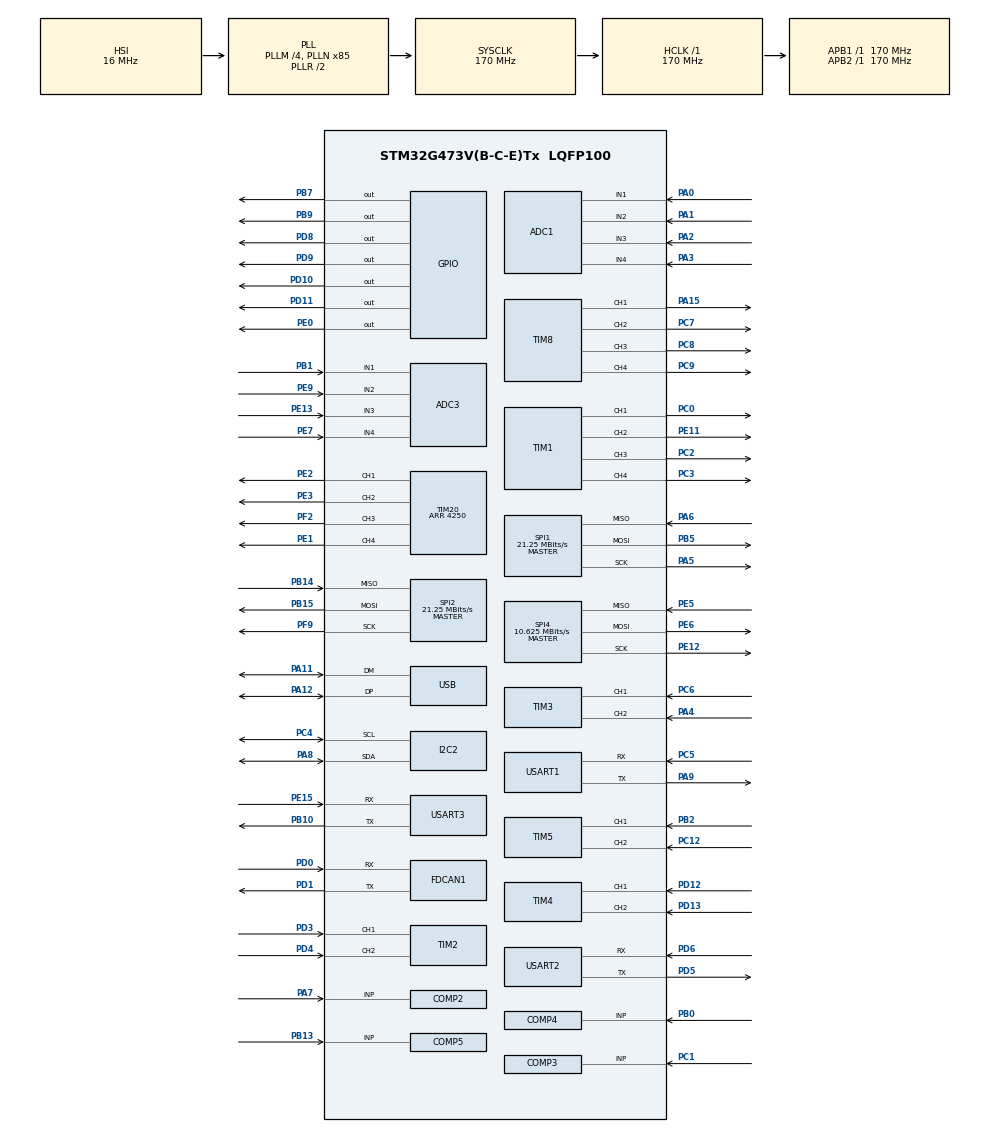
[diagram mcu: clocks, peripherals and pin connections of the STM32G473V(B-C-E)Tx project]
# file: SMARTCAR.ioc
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ADC1.Channel-0\#ChannelRegularConversion=ADC_CHANNEL_1
ADC1.NbrOfConversionFlag=1
ADC1.OffsetNumber-0\#ChannelRegularConversion=ADC_OFFSET_NONE
ADC1.Rank-0\#ChannelRegularConversion=1
ADC1.SamplingTime-0\#ChannelRegularConversion=ADC_SAMPLETIME_2CYCLES_5
ADC1.master=1
ADC3.Channel-0\#ChannelRegularConversion=ADC_CHANNEL_1
ADC3.NbrOfConversionFlag=1
ADC3.OffsetNumber-0\#ChannelRegularConversion=ADC_OFFSET_NONE
ADC3.Rank-0\#ChannelRegularConversion=1
ADC3.SamplingTime-0\#ChannelRegularConversion=ADC_SAMPLETIME_2CYCLES_5
ADC3.master=1
DAC1.DAC_Channel-DAC_OUT2_Int=DAC_CHANNEL_2
DAC3.DAC_Channel-DAC_OUT2_Int=DAC_CHANNEL_2
FDCAN1.CalculateBaudRateNominal=3541666
FDCAN1.CalculateTimeBitNominal=282
FDCAN1.CalculateTimeQuantumNominal=94.11764705882354
FREERTOS.Tasks01=defaultTask,24,128,StartDefaultTask,Default,NULL,Dynamic,NULL,NULL
I2C2.Timing=0x40B285C2
Mcu.Family=STM32G4
Mcu.Name=STM32G473V(B-C-E)Tx
Mcu.Package=LQFP100
NVIC.ADC1_2_IRQn=true\:5\:0\:false\:false\:true\:true\:true\:true\:true
NVIC.PriorityGroup=NVIC_PRIORITYGROUP_4
NVIC.TIM1_UP_TIM16_IRQn=true\:5\:0\:false\:false\:true\:true\:false\:true\:true
NVIC.TIM6_DAC_IRQn=true\:15\:0\:false\:false\:true\:false\:false\:true\:true
NVIC.TIM7_DAC_IRQn=true\:5\:0\:false\:false\:true\:true\:true\:true\:true
NVIC.TimeBase=TIM6_DAC_IRQn
NVIC.TimeBaseIP=TIM6
NVIC.USB_LP_IRQn=true\:5\:0\:false\:false\:true\:true\:false\:true\:true
PA0.Mode=IN1-Single-Ended
PA0.Signal=ADC1_IN1
PA1.Mode=IN2-Single-Ended
PA1.Signal=ADC1_IN2
PA11.Mode=Device
PA11.Signal=USB_DM
PA12.Mode=Device
PA12.Signal=USB_DP
PA13.Mode=Serial_Wire
PA13.Signal=SYS_JTMS-SWDIO
PA14.Mode=Serial_Wire
PA14.Signal=SYS_JTCK-SWCLK
PA15.Signal=S_TIM8_CH1
PA2.Mode=IN3-Single-Ended
PA2.Signal=ADC1_IN3
PA3.Mode=IN4-Single-Ended
PA3.Signal=ADC1_IN4
PA4.Signal=S_TIM3_CH2
PA5.Mode=Full_Duplex_Master
PA5.Signal=SPI1_SCK
PA6.Mode=Full_Duplex_Master
PA6.Signal=SPI1_MISO
PA7.Mode=INP
PA7.Signal=COMP2_INP
PA8.Mode=I2C
PA8.Signal=I2C2_SDA
PA9.Mode=Asynchronous
PA9.Signal=USART1_TX
PB0.Mode=INP
PB0.Signal=COMP4_INP
PB1.Mode=IN1-Single-Ended
PB1.Signal=ADC3_IN1
PB10.Mode=Asynchronous
PB10.Signal=USART3_TX
PB13.Mode=INP
PB13.Signal=COMP5_INP
PB14.Mode=Full_Duplex_Master
PB14.Signal=SPI2_MISO
PB15.Mode=Full_Duplex_Master
PB15.Signal=SPI2_MOSI
PB2.Signal=S_TIM5_CH1
PB5.Mode=Full_Duplex_Master
PB5.Signal=SPI1_MOSI
PB7.Signal=GPIO_Output
PB9.Signal=GPIO_Output
PC0.Signal=S_TIM1_CH1
PC1.Mode=INP
PC1.Signal=COMP3_INP
PC12.Signal=S_TIM5_CH2
PC14-OSC32_IN.Mode=LSE-External-Oscillator
PC14-OSC32_IN.Signal=RCC_OSC32_IN
PC15-OSC32_OUT.Mode=LSE-External-Oscillator
PC15-OSC32_OUT.Signal=RCC_OSC32_OUT
PC2.Signal=S_TIM1_CH3
PC3.Signal=S_TIM1_CH4
PC4.Mode=I2C
PC4.Signal=I2C2_SCL
PC5.Mode=Asynchronous
PC5.Signal=USART1_RX
PC6.Signal=S_TIM3_CH1
PC7.Signal=S_TIM8_CH2
PC8.Signal=S_TIM8_CH3
PC9.Signal=S_TIM8_CH4
PD0.Mode=FDCAN_Activate
PD0.Signal=FDCAN1_RX
PD1.Mode=FDCAN_Activate
PD1.Signal=FDCAN1_TX
PD10.Signal=GPIO_Output
PD11.Signal=GPIO_Output
PD12.Signal=S_TIM4_CH1
PD13.Signal=S_TIM4_CH2
PD3.Signal=S_TIM2_CH1
PD4.Signal=S_TIM2_CH2
PD5.Mode=Asynchronous
PD5.Signal=USART2_TX
PD6.Mode=Asynchronous
PD6.Signal=USART2_RX
PD8.Signal=GPIO_Output
PD9.Signal=GPIO_Output
PE0.Signal=GPIO_Output
PE1.Signal=S_TIM20_CH4
PE11.Signal=S_TIM1_CH2
PE12.Mode=Full_Duplex_Master
PE12.Signal=SPI4_SCK
PE13.Mode=IN3-Single-Ended
PE13.Signal=ADC3_IN3
PE15.Mode=Asynchronous
PE15.Signal=USART3_RX
PE2.Signal=S_TIM20_CH1
PE3.Signal=S_TIM20_CH2
PE5.Mode=Full_Duplex_Master
PE5.Signal=SPI4_MISO
PE6.Mode=Full_Duplex_Master
PE6.Signal=SPI4_MOSI
PE7.Mode=IN4-Single-Ended
PE7.Signal=ADC3_IN4
PE9.Mode=IN2-Single-Ended
PE9.Signal=ADC3_IN2
PF0-OSC_IN.Mode=HSE-External-Oscillator
PF0-OSC_IN.Signal=RCC_OSC_IN
PF1-OSC_OUT.Mode=HSE-External-Oscillator
PF1-OSC_OUT.Signal=RCC_OSC_OUT
PF2.Signal=S_TIM20_CH3
PF9.Mode=Full_Duplex_Master
PF9.Signal=SPI2_SCK
ProjectManager.HeapSize=0x200
ProjectManager.StackSize=0x400
ProjectManager.TargetToolchain=CMake
RCC.ADC12Freq_Value=170000000
RCC.ADC345Freq_Value=170000000
RCC.AHBFreq_Value=170000000
RCC.APB1Freq_Value=170000000
RCC.APB1TimFreq_Value=170000000
RCC.APB2Freq_Value=170000000
RCC.APB2TimFreq_Value=170000000
RCC.CK48CLockSelection=RCC_USBCLKSOURCE_HSI48
RCC.CortexFreq_Value=170000000
RCC.EXTERNAL_CLOCK_VALUE=12288000
RCC.HCLKFreq_Value=170000000
RCC.HSE_VALUE=8000000
RCC.HSI48_VALUE=48000000
RCC.HSI_VALUE=16000000
RCC.PLLM=RCC_PLLM_DIV4
RCC.PLLN=85
RCC.SYSCLKFreq_VALUE=170000000
RCC.SYSCLKSource=RCC_SYSCLKSOURCE_PLLCLK
RCC.USBFreq_Value=48000000
RCC.VCOOutputFreq_Value=340000000
SH.S_TIM1_CH1.0=TIM1_CH1,PWM Generation1 CH1
SH.S_TIM1_CH2.0=TIM1_CH2,PWM Generation2 CH2
SH.S_TIM1_CH3.0=TIM1_CH3,PWM Generation3 CH3
SH.S_TIM1_CH4.0=TIM1_CH4,PWM Generation4 CH4
SH.S_TIM20_CH1.0=TIM20_CH1,PWM Generation1 CH1
SH.S_TIM20_CH2.0=TIM20_CH2,PWM Generation2 CH2
SH.S_TIM20_CH3.0=TIM20_CH3,PWM Generation3 CH3
SH.S_TIM20_CH4.0=TIM20_CH4,PWM Generation4 CH4
SH.S_TIM2_CH1.0=TIM2_CH1,Encoder_Interface
SH.S_TIM2_CH2.0=TIM2_CH2,Encoder_Interface
SH.S_TIM3_CH1.0=TIM3_CH1,Encoder_Interface
SH.S_TIM3_CH2.0=TIM3_CH2,Encoder_Interface
SH.S_TIM4_CH1.0=TIM4_CH1,Encoder_Interface
SH.S_TIM4_CH2.0=TIM4_CH2,Encoder_Interface
SH.S_TIM5_CH1.0=TIM5_CH1,Encoder_Interface
SH.S_TIM5_CH2.0=TIM5_CH2,Encoder_Interface
SH.S_TIM8_CH1.0=TIM8_CH1,PWM Generation1 CH1
SH.S_TIM8_CH2.0=TIM8_CH2,PWM Generation2 CH2
SH.S_TIM8_CH3.0=TIM8_CH3,PWM Generation3 CH3
SH.S_TIM8_CH4.0=TIM8_CH4,PWM Generation4 CH4
SPI1.BaudRatePrescaler=SPI_BAUDRATEPRESCALER_8
SPI1.CalculateBaudRate=21.25 MBits/s
SPI1.Direction=SPI_DIRECTION_2LINES
SPI1.Mode=SPI_MODE_MASTER
SPI1.VirtualType=VM_MASTER
SPI2.BaudRatePrescaler=SPI_BAUDRATEPRESCALER_8
SPI2.CalculateBaudRate=21.25 MBits/s
SPI2.Direction=SPI_DIRECTION_2LINES
SPI2.Mode=SPI_MODE_MASTER
SPI2.VirtualType=VM_MASTER
SPI4.BaudRatePrescaler=SPI_BAUDRATEPRESCALER_16
SPI4.CalculateBaudRate=10.625 MBits/s
SPI4.Direction=SPI_DIRECTION_2LINES
SPI4.Mode=SPI_MODE_MASTER
SPI4.VirtualType=VM_MASTER
TIM1.Channel-PWM\ Generation1\ CH1=TIM_CHANNEL_1
TIM1.Channel-PWM\ Generation2\ CH2=TIM_CHANNEL_2
TIM1.Channel-PWM\ Generation3\ CH3=TIM_CHANNEL_3
TIM1.Channel-PWM\ Generation4\ CH4=TIM_CHANNEL_4
TIM2.EncoderMode=TIM_ENCODERMODE_TI12
TIM20.Channel-PWM\ Generation1\ CH1=TIM_CHANNEL_1
TIM20.Channel-PWM\ Generation2\ CH2=TIM_CHANNEL_2
TIM20.Channel-PWM\ Generation3\ CH3=TIM_CHANNEL_3
TIM20.Channel-PWM\ Generation4\ CH4=TIM_CHANNEL_4
TIM20.PeriodNoDither=4250
TIM3.EncoderMode=TIM_ENCODERMODE_TI12
TIM4.EncoderMode=TIM_ENCODERMODE_TI12
TIM5.EncoderMode=TIM_ENCODERMODE_TI12
TIM7.PeriodNoDither=999
TIM7.Prescaler=169
TIM8.Channel-PWM\ Generation1\ CH1=TIM_CHANNEL_1
TIM8.Channel-PWM\ Generation2\ CH2=TIM_CHANNEL_2
TIM8.Channel-PWM\ Generation3\ CH3=TIM_CHANNEL_3
TIM8.Channel-PWM\ Generation4\ CH4=TIM_CHANNEL_4
USART1.VirtualMode-Asynchronous=VM_ASYNC
USART2.VirtualMode-Asynchronous=VM_ASYNC
USART3.VirtualMode-Asynchronous=VM_ASYNC
USB_DEVICE.CLASS_NAME_FS=CDC
USB_DEVICE.VirtualMode=Cdc
USB_DEVICE.VirtualModeFS=Cdc_FS
VP_ADC1_TempSens_Input.Mode=IN-TempSens
VP_COMP2_VS_DAC1OUT2.Mode=INM_DAC1OUT2
VP_COMP3_VS_DAC1OUT1.Mode=INM_DAC1OUT1
VP_COMP4_VS_DAC3OUT2.Mode=INM_DAC3OUT2
VP_COMP5_VS_DAC4OUT1.Mode=INM_DAC4OUT1
VP_CORDIC_VS_CORDIC.Mode=CORDIC_Activate
VP_CRC_VS_CRC.Mode=CRC_Activate
VP_DAC1_VS_DACI1.Mode=DAC_OUT1_Int
VP_DAC1_VS_DACI2.Mode=DAC_OUT2_Int
VP_DAC3_VS_DACI2.Mode=DAC_OUT2_Int
VP_DAC4_VS_DACI1.Mode=DAC_OUT1_Int
VP_FMAC_VS_FMAC.Mode=FMAC_Activate
VP_FREERTOS_VS_CMSIS_V2.Mode=CMSIS_V2
VP_IWDG_VS_IWDG.Mode=IWDG_Activate
VP_SYS_VS_DBSignals.Mode=DisableDeadBatterySignals
VP_SYS_VS_tim6.Mode=TIM6
VP_TIM7_VS_ClockSourceINT.Mode=Enable_Timer
VP_USB_DEVICE_VS_USB_DEVICE_CDC_FS.Mode=CDC_FS
board=custom

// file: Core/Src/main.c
/* USER CODE BEGIN Header */
/**
  ******************************************************************************
  * @file           : main.c
  * @brief          : Main program body
  ******************************************************************************
  * @attention
  *
  * Copyright (c) 2026 STMicroelectronics.
  * All rights reserved.
  *
  * This software is licensed under terms that can be found in the LICENSE file
  * in the root directory of this software component.
  * If no LICENSE file comes with this software, it is provided AS-IS.
  *
  ******************************************************************************
  */
/* USER CODE END Header */
#include "main.h"

#include "cmsis_os.h"
#include "usb_device.h"

/* USER CODE BEGIN Includes */
#include "app_main.h"
/* USER CODE END Includes */

ADC_HandleTypeDef hadc1;
ADC_HandleTypeDef hadc3;

COMP_HandleTypeDef hcomp2;
COMP_HandleTypeDef hcomp3;
COMP_HandleTypeDef hcomp4;
COMP_HandleTypeDef hcomp5;

CORDIC_HandleTypeDef hcordic;

CRC_HandleTypeDef hcrc;

DAC_HandleTypeDef hdac1;
DAC_HandleTypeDef hdac3;
DAC_HandleTypeDef hdac4;

FDCAN_HandleTypeDef hfdcan1;

FMAC_HandleTypeDef hfmac;

I2C_HandleTypeDef hi2c2;

IWDG_HandleTypeDef hiwdg;

SPI_HandleTypeDef hspi1;
SPI_HandleTypeDef hspi2;
SPI_HandleTypeDef hspi4;

TIM_HandleTypeDef htim1;
TIM_HandleTypeDef htim2;
TIM_HandleTypeDef htim3;
TIM_HandleTypeDef htim4;
TIM_HandleTypeDef htim5;
TIM_HandleTypeDef htim7;
TIM_HandleTypeDef htim8;
TIM_HandleTypeDef htim20;

UART_HandleTypeDef huart1;
UART_HandleTypeDef huart2;
UART_HandleTypeDef huart3;

/* Definitions for defaultTask */
osThreadId_t defaultTaskHandle;
const osThreadAttr_t defaultTask_attributes = {
    .name = "defaultTask",
    .priority = (osPriority_t) osPriorityNormal,
    .stack_size = 128 * 4
};

void SystemClock_Config(void);

static void MX_GPIO_Init(void);

static void MX_ADC1_Init(void);

static void MX_ADC3_Init(void);

static void MX_COMP2_Init(void);

static void MX_COMP3_Init(void);

static void MX_COMP4_Init(void);

static void MX_COMP5_Init(void);

static void MX_CORDIC_Init(void);

static void MX_CRC_Init(void);

static void MX_DAC1_Init(void);

static void MX_DAC3_Init(void);

static void MX_DAC4_Init(void);

static void MX_FDCAN1_Init(void);

static void MX_FMAC_Init(void);

static void MX_I2C2_Init(void);

static void MX_IWDG_Init(void);

static void MX_SPI1_Init(void);

static void MX_SPI2_Init(void);

static void MX_TIM1_Init(void);

static void MX_TIM2_Init(void);

static void MX_TIM3_Init(void);

static void MX_TIM4_Init(void);

static void MX_TIM5_Init(void);

static void MX_TIM8_Init(void);

static void MX_TIM20_Init(void);

static void MX_USART1_UART_Init(void);

static void MX_USART2_UART_Init(void);

static void MX_USART3_UART_Init(void);

static void MX_SPI4_Init(void);

static void MX_TIM7_Init(void);

void StartDefaultTask(void *argument);

int main(void) {

    /* MCU Configuration--------------------------------------------------------*/

    /* Reset of all peripherals, Initializes the Flash interface and the Systick. */
    HAL_Init();

    /* Configure the system clock */
    SystemClock_Config();

    /* Initialize all configured peripherals */
    MX_GPIO_Init();
    MX_ADC1_Init();
    MX_ADC3_Init();
    MX_COMP2_Init();
    MX_COMP3_Init();
    MX_COMP4_Init();
    MX_COMP5_Init();
    MX_CORDIC_Init();
    MX_CRC_Init();
    MX_DAC1_Init();
    MX_DAC3_Init();
    MX_DAC4_Init();
    MX_FDCAN1_Init();
    MX_FMAC_Init();
    MX_I2C2_Init();
    MX_IWDG_Init();
    MX_SPI1_Init();
    MX_SPI2_Init();
    MX_TIM1_Init();
    MX_TIM2_Init();
    MX_TIM3_Init();
    MX_TIM4_Init();
    MX_TIM5_Init();
    MX_TIM8_Init();
    MX_TIM20_Init();
    MX_USART1_UART_Init();
    MX_USART2_UART_Init();
    MX_USART3_UART_Init();
    MX_SPI4_Init();
    MX_TIM7_Init();
    /* USER CODE BEGIN 2 */

    HAL_Delay(100);
    App_Init();
    App_Main();
    /* USER CODE END 2 */

    /* Init scheduler */
    osKernelInitialize();

    /* Create the thread(s) */
    /* creation of defaultTask */
    defaultTaskHandle = osThreadNew(StartDefaultTask, NULL, &defaultTask_attributes);

    /* Start scheduler */
    osKernelStart();

    /* We should never get here as control is now taken by the scheduler */

    /* Infinite loop */
    while (1) {

    }
}

void SystemClock_Config(void) {
    RCC_OscInitTypeDef RCC_OscInitStruct = {0};
    RCC_ClkInitTypeDef RCC_ClkInitStruct = {0};

    /** Configure the main internal regulator output voltage
    */
    HAL_PWREx_ControlVoltageScaling(PWR_REGULATOR_VOLTAGE_SCALE1_BOOST);

    /** Initializes the RCC Oscillators according to the specified parameters
    * in the RCC_OscInitTypeDef structure.
    */
    RCC_OscInitStruct.OscillatorType = RCC_OSCILLATORTYPE_HSI | RCC_OSCILLATORTYPE_HSI48
                                       | RCC_OSCILLATORTYPE_LSI;
    RCC_OscInitStruct.HSIState = RCC_HSI_ON;
    RCC_OscInitStruct.HSICalibrationValue = RCC_HSICALIBRATION_DEFAULT;
    RCC_OscInitStruct.LSIState = RCC_LSI_ON;
    RCC_OscInitStruct.HSI48State = RCC_HSI48_ON;
    RCC_OscInitStruct.PLL.PLLState = RCC_PLL_ON;
    RCC_OscInitStruct.PLL.PLLSource = RCC_PLLSOURCE_HSI;
    RCC_OscInitStruct.PLL.PLLM = RCC_PLLM_DIV4;
    RCC_OscInitStruct.PLL.PLLN = 85;
    RCC_OscInitStruct.PLL.PLLP = RCC_PLLP_DIV2;
    RCC_OscInitStruct.PLL.PLLQ = RCC_PLLQ_DIV2;
    RCC_OscInitStruct.PLL.PLLR = RCC_PLLR_DIV2;
    if (HAL_RCC_OscConfig(&RCC_OscInitStruct) != HAL_OK) {
        Error_Handler();
    }

    /** Initializes the CPU, AHB and APB buses clocks
    */
    RCC_ClkInitStruct.ClockType = RCC_CLOCKTYPE_HCLK | RCC_CLOCKTYPE_SYSCLK
                                  | RCC_CLOCKTYPE_PCLK1 | RCC_CLOCKTYPE_PCLK2;
    RCC_ClkInitStruct.SYSCLKSource = RCC_SYSCLKSOURCE_PLLCLK;
    RCC_ClkInitStruct.AHBCLKDivider = RCC_SYSCLK_DIV1;
    RCC_ClkInitStruct.APB1CLKDivider = RCC_HCLK_DIV1;
    RCC_ClkInitStruct.APB2CLKDivider = RCC_HCLK_DIV1;

    if (HAL_RCC_ClockConfig(&RCC_ClkInitStruct, FLASH_LATENCY_4) != HAL_OK) {
        Error_Handler();
    }
}

static void MX_ADC1_Init(void) {

    ADC_MultiModeTypeDef multimode = {0};
    ADC_ChannelConfTypeDef sConfig = {0};

    /** Common config
    */
    hadc1.Instance = ADC1;
    hadc1.Init.ClockPrescaler = ADC_CLOCK_SYNC_PCLK_DIV4;
    hadc1.Init.Resolution = ADC_RESOLUTION_12B;
    hadc1.Init.DataAlign = ADC_DATAALIGN_RIGHT;
    hadc1.Init.GainCompensation = 0;
    hadc1.Init.ScanConvMode = ADC_SCAN_DISABLE;
    hadc1.Init.EOCSelection = ADC_EOC_SINGLE_CONV;
    hadc1.Init.LowPowerAutoWait = DISABLE;
    hadc1.Init.ContinuousConvMode = DISABLE;
    hadc1.Init.NbrOfConversion = 1;
    hadc1.Init.DiscontinuousConvMode = DISABLE;
    hadc1.Init.ExternalTrigConv = ADC_SOFTWARE_START;
    hadc1.Init.ExternalTrigConvEdge = ADC_EXTERNALTRIGCONVEDGE_NONE;
    hadc1.Init.DMAContinuousRequests = DISABLE;
    hadc1.Init.Overrun = ADC_OVR_DATA_PRESERVED;
    hadc1.Init.OversamplingMode = DISABLE;
    if (HAL_ADC_Init(&hadc1) != HAL_OK) {
        Error_Handler();
    }

    /** Configure the ADC multi-mode
    */
    multimode.Mode = ADC_MODE_INDEPENDENT;
    if (HAL_ADCEx_MultiModeConfigChannel(&hadc1, &multimode) != HAL_OK) {
        Error_Handler();
    }

    /** Configure Regular Channel
    */
    sConfig.Channel = ADC_CHANNEL_1;
    sConfig.Rank = ADC_REGULAR_RANK_1;
    sConfig.SamplingTime = ADC_SAMPLETIME_2CYCLES_5;
    sConfig.SingleDiff = ADC_SINGLE_ENDED;
    sConfig.OffsetNumber = ADC_OFFSET_NONE;
    sConfig.Offset = 0;
    if (HAL_ADC_ConfigChannel(&hadc1, &sConfig) != HAL_OK) {
        Error_Handler();
    }
}

static void MX_ADC3_Init(void) {

    ADC_MultiModeTypeDef multimode = {0};
    ADC_ChannelConfTypeDef sConfig = {0};

    /** Common config
    */
    hadc3.Instance = ADC3;
    hadc3.Init.ClockPrescaler = ADC_CLOCK_SYNC_PCLK_DIV4;
    hadc3.Init.Resolution = ADC_RESOLUTION_12B;
    hadc3.Init.DataAlign = ADC_DATAALIGN_RIGHT;
    hadc3.Init.GainCompensation = 0;
    hadc3.Init.ScanConvMode = ADC_SCAN_DISABLE;
    hadc3.Init.EOCSelection = ADC_EOC_SINGLE_CONV;
    hadc3.Init.LowPowerAutoWait = DISABLE;
    hadc3.Init.ContinuousConvMode = DISABLE;
    hadc3.Init.NbrOfConversion = 1;
    hadc3.Init.DiscontinuousConvMode = DISABLE;
    hadc3.Init.ExternalTrigConv = ADC_SOFTWARE_START;
    hadc3.Init.ExternalTrigConvEdge = ADC_EXTERNALTRIGCONVEDGE_NONE;
    hadc3.Init.DMAContinuousRequests = DISABLE;
    hadc3.Init.Overrun = ADC_OVR_DATA_PRESERVED;
    hadc3.Init.OversamplingMode = DISABLE;
    if (HAL_ADC_Init(&hadc3) != HAL_OK) {
        Error_Handler();
    }

    /** Configure the ADC multi-mode
    */
    multimode.Mode = ADC_MODE_INDEPENDENT;
    if (HAL_ADCEx_MultiModeConfigChannel(&hadc3, &multimode) != HAL_OK) {
        Error_Handler();
    }

    /** Configure Regular Channel
    */
    sConfig.Channel = ADC_CHANNEL_1;
    sConfig.Rank = ADC_REGULAR_RANK_1;
    sConfig.SamplingTime = ADC_SAMPLETIME_2CYCLES_5;
    sConfig.SingleDiff = ADC_SINGLE_ENDED;
    sConfig.OffsetNumber = ADC_OFFSET_NONE;
    sConfig.Offset = 0;
    if (HAL_ADC_ConfigChannel(&hadc3, &sConfig) != HAL_OK) {
        Error_Handler();
    }
}

static void MX_COMP2_Init(void) {

    hcomp2.Instance = COMP2;
    hcomp2.Init.InputPlus = COMP_INPUT_PLUS_IO1;
    hcomp2.Init.InputMinus = COMP_INPUT_MINUS_DAC1_CH2;
    hcomp2.Init.OutputPol = COMP_OUTPUTPOL_NONINVERTED;
    hcomp2.Init.Hysteresis = COMP_HYSTERESIS_NONE;
    hcomp2.Init.BlankingSrce = COMP_BLANKINGSRC_NONE;
    hcomp2.Init.TriggerMode = COMP_TRIGGERMODE_NONE;
    if (HAL_COMP_Init(&hcomp2) != HAL_OK) {
        Error_Handler();
    }
}

static void MX_COMP3_Init(void) {

    hcomp3.Instance = COMP3;
    hcomp3.Init.InputPlus = COMP_INPUT_PLUS_IO2;
    hcomp3.Init.InputMinus = COMP_INPUT_MINUS_DAC1_CH1;
    hcomp3.Init.OutputPol = COMP_OUTPUTPOL_NONINVERTED;
    hcomp3.Init.Hysteresis = COMP_HYSTERESIS_NONE;
    hcomp3.Init.BlankingSrce = COMP_BLANKINGSRC_NONE;
    hcomp3.Init.TriggerMode = COMP_TRIGGERMODE_NONE;
    if (HAL_COMP_Init(&hcomp3) != HAL_OK) {
        Error_Handler();
    }
}

static void MX_COMP4_Init(void) {

    hcomp4.Instance = COMP4;
    hcomp4.Init.InputPlus = COMP_INPUT_PLUS_IO1;
    hcomp4.Init.InputMinus = COMP_INPUT_MINUS_DAC3_CH2;
    hcomp4.Init.OutputPol = COMP_OUTPUTPOL_NONINVERTED;
    hcomp4.Init.Hysteresis = COMP_HYSTERESIS_NONE;
    hcomp4.Init.BlankingSrce = COMP_BLANKINGSRC_NONE;
    hcomp4.Init.TriggerMode = COMP_TRIGGERMODE_NONE;
    if (HAL_COMP_Init(&hcomp4) != HAL_OK) {
        Error_Handler();
    }
}

static void MX_COMP5_Init(void) {

    hcomp5.Instance = COMP5;
    hcomp5.Init.InputPlus = COMP_INPUT_PLUS_IO1;
    hcomp5.Init.InputMinus = COMP_INPUT_MINUS_DAC4_CH1;
    hcomp5.Init.OutputPol = COMP_OUTPUTPOL_NONINVERTED;
    hcomp5.Init.Hysteresis = COMP_HYSTERESIS_NONE;
    hcomp5.Init.BlankingSrce = COMP_BLANKINGSRC_NONE;
    hcomp5.Init.TriggerMode = COMP_TRIGGERMODE_NONE;
    if (HAL_COMP_Init(&hcomp5) != HAL_OK) {
        Error_Handler();
    }
}

static void MX_CORDIC_Init(void) {

    hcordic.Instance = CORDIC;
    if (HAL_CORDIC_Init(&hcordic) != HAL_OK) {
        Error_Handler();
    }
}

static void MX_CRC_Init(void) {

    hcrc.Instance = CRC;
    hcrc.Init.DefaultPolynomialUse = DEFAULT_POLYNOMIAL_ENABLE;
    hcrc.Init.DefaultInitValueUse = DEFAULT_INIT_VALUE_ENABLE;
    hcrc.Init.InputDataInversionMode = CRC_INPUTDATA_INVERSION_NONE;
    hcrc.Init.OutputDataInversionMode = CRC_OUTPUTDATA_INVERSION_DISABLE;
    hcrc.InputDataFormat = CRC_INPUTDATA_FORMAT_BYTES;
    if (HAL_CRC_Init(&hcrc) != HAL_OK) {
        Error_Handler();
    }
}

static void MX_DAC1_Init(void) {

    DAC_ChannelConfTypeDef sConfig = {0};

    /** DAC Initialization
    */
    hdac1.Instance = DAC1;
    if (HAL_DAC_Init(&hdac1) != HAL_OK) {
        Error_Handler();
    }

    /** DAC channel OUT1 config
    */
    sConfig.DAC_HighFrequency = DAC_HIGH_FREQUENCY_INTERFACE_MODE_AUTOMATIC;
    sConfig.DAC_DMADoubleDataMode = DISABLE;
    sConfig.DAC_SignedFormat = DISABLE;
    sConfig.DAC_SampleAndHold = DAC_SAMPLEANDHOLD_DISABLE;
    sConfig.DAC_Trigger = DAC_TRIGGER_NONE;
    sConfig.DAC_Trigger2 = DAC_TRIGGER_NONE;
    sConfig.DAC_OutputBuffer = DAC_OUTPUTBUFFER_DISABLE;
    sConfig.DAC_ConnectOnChipPeripheral = DAC_CHIPCONNECT_INTERNAL;
    sConfig.DAC_UserTrimming = DAC_TRIMMING_FACTORY;
    if (HAL_DAC_ConfigChannel(&hdac1, &sConfig, DAC_CHANNEL_1) != HAL_OK) {
        Error_Handler();
    }

    /** DAC channel OUT2 config
    */
    if (HAL_DAC_ConfigChannel(&hdac1, &sConfig, DAC_CHANNEL_2) != HAL_OK) {
        Error_Handler();
    }
}

static void MX_DAC3_Init(void) {

    DAC_ChannelConfTypeDef sConfig = {0};

    /** DAC Initialization
    */
    hdac3.Instance = DAC3;
    if (HAL_DAC_Init(&hdac3) != HAL_OK) {
        Error_Handler();
    }

    /** DAC channel OUT2 config
    */
    sConfig.DAC_HighFrequency = DAC_HIGH_FREQUENCY_INTERFACE_MODE_AUTOMATIC;
    sConfig.DAC_DMADoubleDataMode = DISABLE;
    sConfig.DAC_SignedFormat = DISABLE;
    sConfig.DAC_SampleAndHold = DAC_SAMPLEANDHOLD_DISABLE;
    sConfig.DAC_Trigger = DAC_TRIGGER_NONE;
    sConfig.DAC_Trigger2 = DAC_TRIGGER_NONE;
    sConfig.DAC_OutputBuffer = DAC_OUTPUTBUFFER_DISABLE;
    sConfig.DAC_ConnectOnChipPeripheral = DAC_CHIPCONNECT_INTERNAL;
    sConfig.DAC_UserTrimming = DAC_TRIMMING_FACTORY;
    if (HAL_DAC_ConfigChannel(&hdac3, &sConfig, DAC_CHANNEL_2) != HAL_OK) {
        Error_Handler();
    }
}

static void MX_DAC4_Init(void) {

    DAC_ChannelConfTypeDef sConfig = {0};

    /** DAC Initialization
    */
    hdac4.Instance = DAC4;
    if (HAL_DAC_Init(&hdac4) != HAL_OK) {
        Error_Handler();
    }

    /** DAC channel OUT1 config
    */
    sConfig.DAC_HighFrequency = DAC_HIGH_FREQUENCY_INTERFACE_MODE_AUTOMATIC;
    sConfig.DAC_DMADoubleDataMode = DISABLE;
    sConfig.DAC_SignedFormat = DISABLE;
    sConfig.DAC_SampleAndHold = DAC_SAMPLEANDHOLD_DISABLE;
    sConfig.DAC_Trigger = DAC_TRIGGER_NONE;
    sConfig.DAC_Trigger2 = DAC_TRIGGER_NONE;
    sConfig.DAC_OutputBuffer = DAC_OUTPUTBUFFER_DISABLE;
    sConfig.DAC_ConnectOnChipPeripheral = DAC_CHIPCONNECT_INTERNAL;
    sConfig.DAC_UserTrimming = DAC_TRIMMING_FACTORY;
    if (HAL_DAC_ConfigChannel(&hdac4, &sConfig, DAC_CHANNEL_1) != HAL_OK) {
        Error_Handler();
    }
}

static void MX_FDCAN1_Init(void) {

    hfdcan1.Instance = FDCAN1;
    hfdcan1.Init.ClockDivider = FDCAN_CLOCK_DIV1;
    hfdcan1.Init.FrameFormat = FDCAN_FRAME_CLASSIC;
    hfdcan1.Init.Mode = FDCAN_MODE_NORMAL;
    hfdcan1.Init.AutoRetransmission = DISABLE;
    hfdcan1.Init.TransmitPause = DISABLE;
    hfdcan1.Init.ProtocolException = DISABLE;
    hfdcan1.Init.NominalPrescaler = 16;
    hfdcan1.Init.NominalSyncJumpWidth = 1;
    hfdcan1.Init.NominalTimeSeg1 = 1;
    hfdcan1.Init.NominalTimeSeg2 = 1;
    hfdcan1.Init.DataPrescaler = 1;
    hfdcan1.Init.DataSyncJumpWidth = 1;
    hfdcan1.Init.DataTimeSeg1 = 1;
    hfdcan1.Init.DataTimeSeg2 = 1;
    hfdcan1.Init.StdFiltersNbr = 0;
    hfdcan1.Init.ExtFiltersNbr = 0;
    hfdcan1.Init.TxFifoQueueMode = FDCAN_TX_FIFO_OPERATION;
    if (HAL_FDCAN_Init(&hfdcan1) != HAL_OK) {
        Error_Handler();
    }
}

static void MX_FMAC_Init(void) {

    hfmac.Instance = FMAC;
    if (HAL_FMAC_Init(&hfmac) != HAL_OK) {
        Error_Handler();
    }
}

static void MX_I2C2_Init(void) {

    hi2c2.Instance = I2C2;
    hi2c2.Init.Timing = 0x40B285C2;
    hi2c2.Init.OwnAddress1 = 0;
    hi2c2.Init.AddressingMode = I2C_ADDRESSINGMODE_7BIT;
    hi2c2.Init.DualAddressMode = I2C_DUALADDRESS_DISABLE;
    hi2c2.Init.OwnAddress2 = 0;
    hi2c2.Init.OwnAddress2Masks = I2C_OA2_NOMASK;
    hi2c2.Init.GeneralCallMode = I2C_GENERALCALL_DISABLE;
    hi2c2.Init.NoStretchMode = I2C_NOSTRETCH_DISABLE;
    if (HAL_I2C_Init(&hi2c2) != HAL_OK) {
        Error_Handler();
    }

    /** Configure Analogue filter
    */
    if (HAL_I2CEx_ConfigAnalogFilter(&hi2c2, I2C_ANALOGFILTER_ENABLE) != HAL_OK) {
        Error_Handler();
    }

    /** Configure Digital filter
    */
    if (HAL_I2CEx_ConfigDigitalFilter(&hi2c2, 0) != HAL_OK) {
        Error_Handler();
    }
}

static void MX_IWDG_Init(void) {

    hiwdg.Instance = IWDG;
    hiwdg.Init.Prescaler = IWDG_PRESCALER_4;
    hiwdg.Init.Window = 4095;
    hiwdg.Init.Reload = 4095;
    if (HAL_IWDG_Init(&hiwdg) != HAL_OK) {
        Error_Handler();
    }
}

static void MX_SPI1_Init(void) {

    /* SPI1 parameter configuration*/
    hspi1.Instance = SPI1;
    hspi1.Init.Mode = SPI_MODE_MASTER;
    hspi1.Init.Direction = SPI_DIRECTION_2LINES;
    hspi1.Init.DataSize = SPI_DATASIZE_4BIT;
    hspi1.Init.CLKPolarity = SPI_POLARITY_LOW;
    hspi1.Init.CLKPhase = SPI_PHASE_1EDGE;
    hspi1.Init.NSS = SPI_NSS_SOFT;
    hspi1.Init.BaudRatePrescaler = SPI_BAUDRATEPRESCALER_8;
    hspi1.Init.FirstBit = SPI_FIRSTBIT_MSB;
    hspi1.Init.TIMode = SPI_TIMODE_DISABLE;
    hspi1.Init.CRCCalculation = SPI_CRCCALCULATION_DISABLE;
    hspi1.Init.CRCPolynomial = 7;
    hspi1.Init.CRCLength = SPI_CRC_LENGTH_DATASIZE;
    hspi1.Init.NSSPMode = SPI_NSS_PULSE_ENABLE;
    if (HAL_SPI_Init(&hspi1) != HAL_OK) {
        Error_Handler();
    }
}

static void MX_SPI2_Init(void) {

    /* SPI2 parameter configuration*/
    hspi2.Instance = SPI2;
    hspi2.Init.Mode = SPI_MODE_MASTER;
    hspi2.Init.Direction = SPI_DIRECTION_2LINES;
    hspi2.Init.DataSize = SPI_DATASIZE_4BIT;
    hspi2.Init.CLKPolarity = SPI_POLARITY_LOW;
    hspi2.Init.CLKPhase = SPI_PHASE_1EDGE;
    hspi2.Init.NSS = SPI_NSS_SOFT;
    hspi2.Init.BaudRatePrescaler = SPI_BAUDRATEPRESCALER_8;
    hspi2.Init.FirstBit = SPI_FIRSTBIT_MSB;
    hspi2.Init.TIMode = SPI_TIMODE_DISABLE;
    hspi2.Init.CRCCalculation = SPI_CRCCALCULATION_DISABLE;
    hspi2.Init.CRCPolynomial = 7;
    hspi2.Init.CRCLength = SPI_CRC_LENGTH_DATASIZE;
    hspi2.Init.NSSPMode = SPI_NSS_PULSE_ENABLE;
    if (HAL_SPI_Init(&hspi2) != HAL_OK) {
        Error_Handler();
    }
}

static void MX_SPI4_Init(void) {

    /* SPI4 parameter configuration*/
    hspi4.Instance = SPI4;
    hspi4.Init.Mode = SPI_MODE_MASTER;
    hspi4.Init.Direction = SPI_DIRECTION_2LINES;
    hspi4.Init.DataSize = SPI_DATASIZE_4BIT;
    hspi4.Init.CLKPolarity = SPI_POLARITY_LOW;
    hspi4.Init.CLKPhase = SPI_PHASE_1EDGE;
    hspi4.Init.NSS = SPI_NSS_SOFT;
    hspi4.Init.BaudRatePrescaler = SPI_BAUDRATEPRESCALER_16;
    hspi4.Init.FirstBit = SPI_FIRSTBIT_MSB;
    hspi4.Init.TIMode = SPI_TIMODE_DISABLE;
    hspi4.Init.CRCCalculation = SPI_CRCCALCULATION_DISABLE;
    hspi4.Init.CRCPolynomial = 7;
    hspi4.Init.CRCLength = SPI_CRC_LENGTH_DATASIZE;
    hspi4.Init.NSSPMode = SPI_NSS_PULSE_ENABLE;
    if (HAL_SPI_Init(&hspi4) != HAL_OK) {
        Error_Handler();
    }
}

static void MX_TIM1_Init(void) {

    TIM_MasterConfigTypeDef sMasterConfig = {0};
    TIM_OC_InitTypeDef sConfigOC = {0};
    TIM_BreakDeadTimeConfigTypeDef sBreakDeadTimeConfig = {0};

    htim1.Instance = TIM1;
    htim1.Init.Prescaler = 0;
    htim1.Init.CounterMode = TIM_COUNTERMODE_UP;
    htim1.Init.Period = 65535;
    htim1.Init.ClockDivision = TIM_CLOCKDIVISION_DIV1;
    htim1.Init.RepetitionCounter = 0;
    htim1.Init.AutoReloadPreload = TIM_AUTORELOAD_PRELOAD_DISABLE;
    if (HAL_TIM_PWM_Init(&htim1) != HAL_OK) {
        Error_Handler();
    }
    sMasterConfig.MasterOutputTrigger = TIM_TRGO_RESET;
    sMasterConfig.MasterOutputTrigger2 = TIM_TRGO2_RESET;
    sMasterConfig.MasterSlaveMode = TIM_MASTERSLAVEMODE_DISABLE;
    if (HAL_TIMEx_MasterConfigSynchronization(&htim1, &sMasterConfig) != HAL_OK) {
        Error_Handler();
    }
    sConfigOC.OCMode = TIM_OCMODE_PWM1;
    sConfigOC.Pulse = 0;
    sConfigOC.OCPolarity = TIM_OCPOLARITY_HIGH;
    sConfigOC.OCNPolarity = TIM_OCNPOLARITY_HIGH;
    sConfigOC.OCFastMode = TIM_OCFAST_DISABLE;
    sConfigOC.OCIdleState = TIM_OCIDLESTATE_RESET;
    sConfigOC.OCNIdleState = TIM_OCNIDLESTATE_RESET;
    if (HAL_TIM_PWM_ConfigChannel(&htim1, &sConfigOC, TIM_CHANNEL_1) != HAL_OK) {
        Error_Handler();
    }
    if (HAL_TIM_PWM_ConfigChannel(&htim1, &sConfigOC, TIM_CHANNEL_2) != HAL_OK) {
        Error_Handler();
    }
    if (HAL_TIM_PWM_ConfigChannel(&htim1, &sConfigOC, TIM_CHANNEL_3) != HAL_OK) {
        Error_Handler();
    }
    if (HAL_TIM_PWM_ConfigChannel(&htim1, &sConfigOC, TIM_CHANNEL_4) != HAL_OK) {
        Error_Handler();
    }
    sBreakDeadTimeConfig.OffStateRunMode = TIM_OSSR_DISABLE;
    sBreakDeadTimeConfig.OffStateIDLEMode = TIM_OSSI_DISABLE;
    sBreakDeadTimeConfig.LockLevel = TIM_LOCKLEVEL_OFF;
    sBreakDeadTimeConfig.DeadTime = 0;
    sBreakDeadTimeConfig.BreakState = TIM_BREAK_DISABLE;
    sBreakDeadTimeConfig.BreakPolarity = TIM_BREAKPOLARITY_HIGH;
    sBreakDeadTimeConfig.BreakFilter = 0;
    sBreakDeadTimeConfig.BreakAFMode = TIM_BREAK_AFMODE_INPUT;
    sBreakDeadTimeConfig.Break2State = TIM_BREAK2_DISABLE;
    sBreakDeadTimeConfig.Break2Polarity = TIM_BREAK2POLARITY_HIGH;
    sBreakDeadTimeConfig.Break2Filter = 0;
    sBreakDeadTimeConfig.Break2AFMode = TIM_BREAK_AFMODE_INPUT;
    sBreakDeadTimeConfig.AutomaticOutput = TIM_AUTOMATICOUTPUT_DISABLE;
    if (HAL_TIMEx_ConfigBreakDeadTime(&htim1, &sBreakDeadTimeConfig) != HAL_OK) {
        Error_Handler();
    }
    HAL_TIM_MspPostInit(&htim1);
}

static void MX_TIM2_Init(void) {

    TIM_Encoder_InitTypeDef sConfig = {0};
    TIM_MasterConfigTypeDef sMasterConfig = {0};

    htim2.Instance = TIM2;
    htim2.Init.Prescaler = 0;
    htim2.Init.CounterMode = TIM_COUNTERMODE_UP;
    htim2.Init.Period = 4294967295;
    htim2.Init.ClockDivision = TIM_CLOCKDIVISION_DIV1;
    htim2.Init.AutoReloadPreload = TIM_AUTORELOAD_PRELOAD_DISABLE;
    sConfig.EncoderMode = TIM_ENCODERMODE_TI12;
    sConfig.IC1Polarity = TIM_ICPOLARITY_RISING;
    sConfig.IC1Selection = TIM_ICSELECTION_DIRECTTI;
    sConfig.IC1Prescaler = TIM_ICPSC_DIV1;
    sConfig.IC1Filter = 0;
    sConfig.IC2Polarity = TIM_ICPOLARITY_RISING;
    sConfig.IC2Selection = TIM_ICSELECTION_DIRECTTI;
    sConfig.IC2Prescaler = TIM_ICPSC_DIV1;
    sConfig.IC2Filter = 0;
    if (HAL_TIM_Encoder_Init(&htim2, &sConfig) != HAL_OK) {
        Error_Handler();
    }
    sMasterConfig.MasterOutputTrigger = TIM_TRGO_RESET;
    sMasterConfig.MasterSlaveMode = TIM_MASTERSLAVEMODE_DISABLE;
    if (HAL_TIMEx_MasterConfigSynchronization(&htim2, &sMasterConfig) != HAL_OK) {
        Error_Handler();
    }
}

static void MX_TIM3_Init(void) {

    TIM_Encoder_InitTypeDef sConfig = {0};
    TIM_MasterConfigTypeDef sMasterConfig = {0};

    htim3.Instance = TIM3;
    htim3.Init.Prescaler = 0;
    htim3.Init.CounterMode = TIM_COUNTERMODE_UP;
    htim3.Init.Period = 65535;
    htim3.Init.ClockDivision = TIM_CLOCKDIVISION_DIV1;
    htim3.Init.AutoReloadPreload = TIM_AUTORELOAD_PRELOAD_DISABLE;
    sConfig.EncoderMode = TIM_ENCODERMODE_TI12;
    sConfig.IC1Polarity = TIM_ICPOLARITY_RISING;
    sConfig.IC1Selection = TIM_ICSELECTION_DIRECTTI;
    sConfig.IC1Prescaler = TIM_ICPSC_DIV1;
    sConfig.IC1Filter = 0;
    sConfig.IC2Polarity = TIM_ICPOLARITY_RISING;
    sConfig.IC2Selection = TIM_ICSELECTION_DIRECTTI;
    sConfig.IC2Prescaler = TIM_ICPSC_DIV1;
    sConfig.IC2Filter = 0;
    if (HAL_TIM_Encoder_Init(&htim3, &sConfig) != HAL_OK) {
        Error_Handler();
    }
    sMasterConfig.MasterOutputTrigger = TIM_TRGO_RESET;
    sMasterConfig.MasterSlaveMode = TIM_MASTERSLAVEMODE_DISABLE;
    if (HAL_TIMEx_MasterConfigSynchronization(&htim3, &sMasterConfig) != HAL_OK) {
        Error_Handler();
    }
}

static void MX_TIM4_Init(void) {

    TIM_Encoder_InitTypeDef sConfig = {0};
    TIM_MasterConfigTypeDef sMasterConfig = {0};

    htim4.Instance = TIM4;
    htim4.Init.Prescaler = 0;
    htim4.Init.CounterMode = TIM_COUNTERMODE_UP;
    htim4.Init.Period = 65535;
    htim4.Init.ClockDivision = TIM_CLOCKDIVISION_DIV1;
    htim4.Init.AutoReloadPreload = TIM_AUTORELOAD_PRELOAD_DISABLE;
    sConfig.EncoderMode = TIM_ENCODERMODE_TI12;
    sConfig.IC1Polarity = TIM_ICPOLARITY_RISING;
    sConfig.IC1Selection = TIM_ICSELECTION_DIRECTTI;
    sConfig.IC1Prescaler = TIM_ICPSC_DIV1;
    sConfig.IC1Filter = 0;
    sConfig.IC2Polarity = TIM_ICPOLARITY_RISING;
    sConfig.IC2Selection = TIM_ICSELECTION_DIRECTTI;
    sConfig.IC2Prescaler = TIM_ICPSC_DIV1;
    sConfig.IC2Filter = 0;
    if (HAL_TIM_Encoder_Init(&htim4, &sConfig) != HAL_OK) {
        Error_Handler();
    }
    sMasterConfig.MasterOutputTrigger = TIM_TRGO_RESET;
    sMasterConfig.MasterSlaveMode = TIM_MASTERSLAVEMODE_DISABLE;
    if (HAL_TIMEx_MasterConfigSynchronization(&htim4, &sMasterConfig) != HAL_OK) {
        Error_Handler();
    }
}

static void MX_TIM5_Init(void) {

    TIM_Encoder_InitTypeDef sConfig = {0};
    TIM_MasterConfigTypeDef sMasterConfig = {0};

    htim5.Instance = TIM5;
    htim5.Init.Prescaler = 0;
    htim5.Init.CounterMode = TIM_COUNTERMODE_UP;
    htim5.Init.Period = 4294967295;
    htim5.Init.ClockDivision = TIM_CLOCKDIVISION_DIV1;
    htim5.Init.AutoReloadPreload = TIM_AUTORELOAD_PRELOAD_DISABLE;
    sConfig.EncoderMode = TIM_ENCODERMODE_TI12;
    sConfig.IC1Polarity = TIM_ICPOLARITY_RISING;
    sConfig.IC1Selection = TIM_ICSELECTION_DIRECTTI;
    sConfig.IC1Prescaler = TIM_ICPSC_DIV1;
    sConfig.IC1Filter = 0;
    sConfig.IC2Polarity = TIM_ICPOLARITY_RISING;
    sConfig.IC2Selection = TIM_ICSELECTION_DIRECTTI;
    sConfig.IC2Prescaler = TIM_ICPSC_DIV1;
    sConfig.IC2Filter = 0;
    if (HAL_TIM_Encoder_Init(&htim5, &sConfig) != HAL_OK) {
        Error_Handler();
    }
    sMasterConfig.MasterOutputTrigger = TIM_TRGO_RESET;
    sMasterConfig.MasterSlaveMode = TIM_MASTERSLAVEMODE_DISABLE;
    if (HAL_TIMEx_MasterConfigSynchronization(&htim5, &sMasterConfig) != HAL_OK) {
        Error_Handler();
    }
}

static void MX_TIM7_Init(void) {

    TIM_MasterConfigTypeDef sMasterConfig = {0};

    htim7.Instance = TIM7;
    htim7.Init.Prescaler = 169;
    htim7.Init.CounterMode = TIM_COUNTERMODE_UP;
    htim7.Init.Period = 999;
    htim7.Init.AutoReloadPreload = TIM_AUTORELOAD_PRELOAD_DISABLE;
    if (HAL_TIM_Base_Init(&htim7) != HAL_OK) {
        Error_Handler();
    }
    sMasterConfig.MasterOutputTrigger = TIM_TRGO_RESET;
    sMasterConfig.MasterSlaveMode = TIM_MASTERSLAVEMODE_DISABLE;
    if (HAL_TIMEx_MasterConfigSynchronization(&htim7, &sMasterConfig) != HAL_OK) {
        Error_Handler();
    }
}

static void MX_TIM8_Init(void) {

    TIM_MasterConfigTypeDef sMasterConfig = {0};
    TIM_OC_InitTypeDef sConfigOC = {0};
    TIM_BreakDeadTimeConfigTypeDef sBreakDeadTimeConfig = {0};

    htim8.Instance = TIM8;
    htim8.Init.Prescaler = 0;
    htim8.Init.CounterMode = TIM_COUNTERMODE_UP;
    htim8.Init.Period = 65535;
    htim8.Init.ClockDivision = TIM_CLOCKDIVISION_DIV1;
    htim8.Init.RepetitionCounter = 0;
    htim8.Init.AutoReloadPreload = TIM_AUTORELOAD_PRELOAD_DISABLE;
    if (HAL_TIM_PWM_Init(&htim8) != HAL_OK) {
        Error_Handler();
    }
    sMasterConfig.MasterOutputTrigger = TIM_TRGO_RESET;
    sMasterConfig.MasterOutputTrigger2 = TIM_TRGO2_RESET;
    sMasterConfig.MasterSlaveMode = TIM_MASTERSLAVEMODE_DISABLE;
    if (HAL_TIMEx_MasterConfigSynchronization(&htim8, &sMasterConfig) != HAL_OK) {
        Error_Handler();
    }
    sConfigOC.OCMode = TIM_OCMODE_PWM1;
    sConfigOC.Pulse = 0;
    sConfigOC.OCPolarity = TIM_OCPOLARITY_HIGH;
    sConfigOC.OCNPolarity = TIM_OCNPOLARITY_HIGH;
    sConfigOC.OCFastMode = TIM_OCFAST_DISABLE;
    sConfigOC.OCIdleState = TIM_OCIDLESTATE_RESET;
    sConfigOC.OCNIdleState = TIM_OCNIDLESTATE_RESET;
    if (HAL_TIM_PWM_ConfigChannel(&htim8, &sConfigOC, TIM_CHANNEL_1) != HAL_OK) {
        Error_Handler();
    }
    if (HAL_TIM_PWM_ConfigChannel(&htim8, &sConfigOC, TIM_CHANNEL_2) != HAL_OK) {
        Error_Handler();
    }
    if (HAL_TIM_PWM_ConfigChannel(&htim8, &sConfigOC, TIM_CHANNEL_3) != HAL_OK) {
        Error_Handler();
    }
    if (HAL_TIM_PWM_ConfigChannel(&htim8, &sConfigOC, TIM_CHANNEL_4) != HAL_OK) {
        Error_Handler();
    }
    sBreakDeadTimeConfig.OffStateRunMode = TIM_OSSR_DISABLE;
    sBreakDeadTimeConfig.OffStateIDLEMode = TIM_OSSI_DISABLE;
    sBreakDeadTimeConfig.LockLevel = TIM_LOCKLEVEL_OFF;
    sBreakDeadTimeConfig.DeadTime = 0;
    sBreakDeadTimeConfig.BreakState = TIM_BREAK_DISABLE;
    sBreakDeadTimeConfig.BreakPolarity = TIM_BREAKPOLARITY_HIGH;
    sBreakDeadTimeConfig.BreakFilter = 0;
    sBreakDeadTimeConfig.BreakAFMode = TIM_BREAK_AFMODE_INPUT;
    sBreakDeadTimeConfig.Break2State = TIM_BREAK2_DISABLE;
    sBreakDeadTimeConfig.Break2Polarity = TIM_BREAK2POLARITY_HIGH;
    sBreakDeadTimeConfig.Break2Filter = 0;
    sBreakDeadTimeConfig.Break2AFMode = TIM_BREAK_AFMODE_INPUT;
    sBreakDeadTimeConfig.AutomaticOutput = TIM_AUTOMATICOUTPUT_DISABLE;
    if (HAL_TIMEx_ConfigBreakDeadTime(&htim8, &sBreakDeadTimeConfig) != HAL_OK) {
        Error_Handler();
    }
    HAL_TIM_MspPostInit(&htim8);
}

static void MX_TIM20_Init(void) {

    TIM_MasterConfigTypeDef sMasterConfig = {0};
    TIM_OC_InitTypeDef sConfigOC = {0};
    TIM_BreakDeadTimeConfigTypeDef sBreakDeadTimeConfig = {0};

    htim20.Instance = TIM20;
    htim20.Init.Prescaler = 0;
    htim20.Init.CounterMode = TIM_COUNTERMODE_UP;
    htim20.Init.Period = 4250;
    htim20.Init.ClockDivision = TIM_CLOCKDIVISION_DIV1;
    htim20.Init.RepetitionCounter = 0;
    htim20.Init.AutoReloadPreload = TIM_AUTORELOAD_PRELOAD_DISABLE;
    if (HAL_TIM_PWM_Init(&htim20) != HAL_OK) {
        Error_Handler();
    }
    sMasterConfig.MasterOutputTrigger = TIM_TRGO_RESET;
    sMasterConfig.MasterOutputTrigger2 = TIM_TRGO2_RESET;
    sMasterConfig.MasterSlaveMode = TIM_MASTERSLAVEMODE_DISABLE;
    if (HAL_TIMEx_MasterConfigSynchronization(&htim20, &sMasterConfig) != HAL_OK) {
        Error_Handler();
    }
    sConfigOC.OCMode = TIM_OCMODE_PWM1;
    sConfigOC.Pulse = 0;
    sConfigOC.OCPolarity = TIM_OCPOLARITY_HIGH;
    sConfigOC.OCNPolarity = TIM_OCNPOLARITY_HIGH;
    sConfigOC.OCFastMode = TIM_OCFAST_DISABLE;
    sConfigOC.OCIdleState = TIM_OCIDLESTATE_RESET;
    sConfigOC.OCNIdleState = TIM_OCNIDLESTATE_RESET;
    if (HAL_TIM_PWM_ConfigChannel(&htim20, &sConfigOC, TIM_CHANNEL_1) != HAL_OK) {
        Error_Handler();
    }
    if (HAL_TIM_PWM_ConfigChannel(&htim20, &sConfigOC, TIM_CHANNEL_2) != HAL_OK) {
        Error_Handler();
    }
    if (HAL_TIM_PWM_ConfigChannel(&htim20, &sConfigOC, TIM_CHANNEL_3) != HAL_OK) {
        Error_Handler();
    }
    if (HAL_TIM_PWM_ConfigChannel(&htim20, &sConfigOC, TIM_CHANNEL_4) != HAL_OK) {
        Error_Handler();
    }
    sBreakDeadTimeConfig.OffStateRunMode = TIM_OSSR_DISABLE;
    sBreakDeadTimeConfig.OffStateIDLEMode = TIM_OSSI_DISABLE;
    sBreakDeadTimeConfig.LockLevel = TIM_LOCKLEVEL_OFF;
    sBreakDeadTimeConfig.DeadTime = 0;
    sBreakDeadTimeConfig.BreakState = TIM_BREAK_DISABLE;
    sBreakDeadTimeConfig.BreakPolarity = TIM_BREAKPOLARITY_HIGH;
    sBreakDeadTimeConfig.BreakFilter = 0;
    sBreakDeadTimeConfig.BreakAFMode = TIM_BREAK_AFMODE_INPUT;
    sBreakDeadTimeConfig.Break2State = TIM_BREAK2_DISABLE;
    sBreakDeadTimeConfig.Break2Polarity = TIM_BREAK2POLARITY_HIGH;
    sBreakDeadTimeConfig.Break2Filter = 0;
    sBreakDeadTimeConfig.Break2AFMode = TIM_BREAK_AFMODE_INPUT;
    sBreakDeadTimeConfig.AutomaticOutput = TIM_AUTOMATICOUTPUT_DISABLE;
    if (HAL_TIMEx_ConfigBreakDeadTime(&htim20, &sBreakDeadTimeConfig) != HAL_OK) {
        Error_Handler();
    }
    HAL_TIM_MspPostInit(&htim20);
}

static void MX_USART1_UART_Init(void) {

    huart1.Instance = USART1;
    huart1.Init.BaudRate = 115200;
    huart1.Init.WordLength = UART_WORDLENGTH_8B;
    huart1.Init.StopBits = UART_STOPBITS_1;
    huart1.Init.Parity = UART_PARITY_NONE;
    huart1.Init.Mode = UART_MODE_TX_RX;
    huart1.Init.HwFlowCtl = UART_HWCONTROL_NONE;
    huart1.Init.OverSampling = UART_OVERSAMPLING_16;
    huart1.Init.OneBitSampling = UART_ONE_BIT_SAMPLE_DISABLE;
    huart1.Init.ClockPrescaler = UART_PRESCALER_DIV1;
    huart1.AdvancedInit.AdvFeatureInit = UART_ADVFEATURE_NO_INIT;
    if (HAL_UART_Init(&huart1) != HAL_OK) {
        Error_Handler();
    }
    if (HAL_UARTEx_SetTxFifoThreshold(&huart1, UART_TXFIFO_THRESHOLD_1_8) != HAL_OK) {
        Error_Handler();
    }
    if (HAL_UARTEx_SetRxFifoThreshold(&huart1, UART_RXFIFO_THRESHOLD_1_8) != HAL_OK) {
        Error_Handler();
    }
    if (HAL_UARTEx_DisableFifoMode(&huart1) != HAL_OK) {
        Error_Handler();
    }
}

static void MX_USART2_UART_Init(void) {

    huart2.Instance = USART2;
    huart2.Init.BaudRate = 115200;
    huart2.Init.WordLength = UART_WORDLENGTH_8B;
    huart2.Init.StopBits = UART_STOPBITS_1;
    huart2.Init.Parity = UART_PARITY_NONE;
    huart2.Init.Mode = UART_MODE_TX_RX;
    huart2.Init.HwFlowCtl = UART_HWCONTROL_NONE;
    huart2.Init.OverSampling = UART_OVERSAMPLING_16;
    huart2.Init.OneBitSampling = UART_ONE_BIT_SAMPLE_DISABLE;
    huart2.Init.ClockPrescaler = UART_PRESCALER_DIV1;
    huart2.AdvancedInit.AdvFeatureInit = UART_ADVFEATURE_NO_INIT;
    if (HAL_UART_Init(&huart2) != HAL_OK) {
        Error_Handler();
    }
    if (HAL_UARTEx_SetTxFifoThreshold(&huart2, UART_TXFIFO_THRESHOLD_1_8) != HAL_OK) {
        Error_Handler();
    }
    if (HAL_UARTEx_SetRxFifoThreshold(&huart2, UART_RXFIFO_THRESHOLD_1_8) != HAL_OK) {
        Error_Handler();
    }
    if (HAL_UARTEx_DisableFifoMode(&huart2) != HAL_OK) {
        Error_Handler();
    }
}

static void MX_USART3_UART_Init(void) {

    huart3.Instance = USART3;
    huart3.Init.BaudRate = 115200;
    huart3.Init.WordLength = UART_WORDLENGTH_8B;
    huart3.Init.StopBits = UART_STOPBITS_1;
    huart3.Init.Parity = UART_PARITY_NONE;
    huart3.Init.Mode = UART_MODE_TX_RX;
    huart3.Init.HwFlowCtl = UART_HWCONTROL_NONE;
    huart3.Init.OverSampling = UART_OVERSAMPLING_16;
    huart3.Init.OneBitSampling = UART_ONE_BIT_SAMPLE_DISABLE;
    huart3.Init.ClockPrescaler = UART_PRESCALER_DIV1;
    huart3.AdvancedInit.AdvFeatureInit = UART_ADVFEATURE_NO_INIT;
    if (HAL_UART_Init(&huart3) != HAL_OK) {
        Error_Handler();
    }
    if (HAL_UARTEx_SetTxFifoThreshold(&huart3, UART_TXFIFO_THRESHOLD_1_8) != HAL_OK) {
        Error_Handler();
    }
    if (HAL_UARTEx_SetRxFifoThreshold(&huart3, UART_RXFIFO_THRESHOLD_1_8) != HAL_OK) {
        Error_Handler();
    }
    if (HAL_UARTEx_DisableFifoMode(&huart3) != HAL_OK) {
        Error_Handler();
    }
}

static void MX_GPIO_Init(void) {
    GPIO_InitTypeDef GPIO_InitStruct = {0};

    /* GPIO Ports Clock Enable */
    __HAL_RCC_GPIOE_CLK_ENABLE();
    __HAL_RCC_GPIOC_CLK_ENABLE();
    __HAL_RCC_GPIOF_CLK_ENABLE();
    __HAL_RCC_GPIOA_CLK_ENABLE();
    __HAL_RCC_GPIOB_CLK_ENABLE();
    __HAL_RCC_GPIOD_CLK_ENABLE();

    /*Configure GPIO pin Output Level */
    HAL_GPIO_WritePin(GPIOD, GPIO_PIN_8 | GPIO_PIN_9 | GPIO_PIN_10 | GPIO_PIN_11, GPIO_PIN_RESET);

    /*Configure GPIO pin Output Level */
    HAL_GPIO_WritePin(GPIOB, GPIO_PIN_7 | GPIO_PIN_9, GPIO_PIN_RESET);

    /*Configure GPIO pin Output Level */
    HAL_GPIO_WritePin(GPIOE, GPIO_PIN_0, GPIO_PIN_RESET);

    /*Configure GPIO pins : PD8 PD9 PD10 PD11 */
    GPIO_InitStruct.Pin = GPIO_PIN_8 | GPIO_PIN_9 | GPIO_PIN_10 | GPIO_PIN_11;
    GPIO_InitStruct.Mode = GPIO_MODE_OUTPUT_PP;
    GPIO_InitStruct.Pull = GPIO_NOPULL;
    GPIO_InitStruct.Speed = GPIO_SPEED_FREQ_LOW;
    HAL_GPIO_Init(GPIOD, &GPIO_InitStruct);

    /*Configure GPIO pins : PB7 PB9 */
    GPIO_InitStruct.Pin = GPIO_PIN_7 | GPIO_PIN_9;
    GPIO_InitStruct.Mode = GPIO_MODE_OUTPUT_PP;
    GPIO_InitStruct.Pull = GPIO_NOPULL;
    GPIO_InitStruct.Speed = GPIO_SPEED_FREQ_LOW;
    HAL_GPIO_Init(GPIOB, &GPIO_InitStruct);

    /*Configure GPIO pin : PE0 */
    GPIO_InitStruct.Pin = GPIO_PIN_0;
    GPIO_InitStruct.Mode = GPIO_MODE_OUTPUT_PP;
    GPIO_InitStruct.Pull = GPIO_NOPULL;
    GPIO_InitStruct.Speed = GPIO_SPEED_FREQ_LOW;
    HAL_GPIO_Init(GPIOE, &GPIO_InitStruct);

}

void StartDefaultTask(void *argument) {
    /* init code for USB_Device */
    MX_USB_Device_Init();
    for (;;) {
        osDelay(1);
    }
}

void HAL_TIM_PeriodElapsedCallback(TIM_HandleTypeDef *htim) {
    if (htim->Instance == TIM6) {
        HAL_IncTick();
    }
    /* USER CODE BEGIN Callback 1 */
    App_TIM_PeriodElapsedCallback(htim);
    /* USER CODE END Callback 1 */
}

void Error_Handler(void) {
    __disable_irq();
    while (1) {
    }
}
